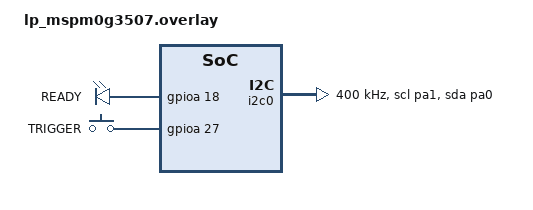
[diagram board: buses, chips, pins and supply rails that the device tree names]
/*
 * I2C Target Test - Target Board Overlay
 */

/ {
	aliases {
		i2c-target = &i2c0;
		ready-gpio = &led_ready;
		trigger-gpio = &button_trigger;
	};

	gpio_leds {
		compatible = "gpio-leds";
		led_ready: led_ready {
			gpios = <&gpioa 18 GPIO_ACTIVE_HIGH>; /* PA18 - READY output */
			label = "READY";
		};
	};

	gpio_keys {
		compatible = "gpio-keys";
		button_trigger: button_trigger {
			gpios = <&gpioa 27 (GPIO_ACTIVE_HIGH | GPIO_PULL_DOWN)>; /* PA27 - TRIGGER input */
			label = "TRIGGER";
		};
	};
};

&i2c0 {
	pinctrl-0 = <&i2c0_scl_pa1 &i2c0_sda_pa0>;
	pinctrl-names = "default";
	clock-frequency = <400000>;
	status = "okay";
};
